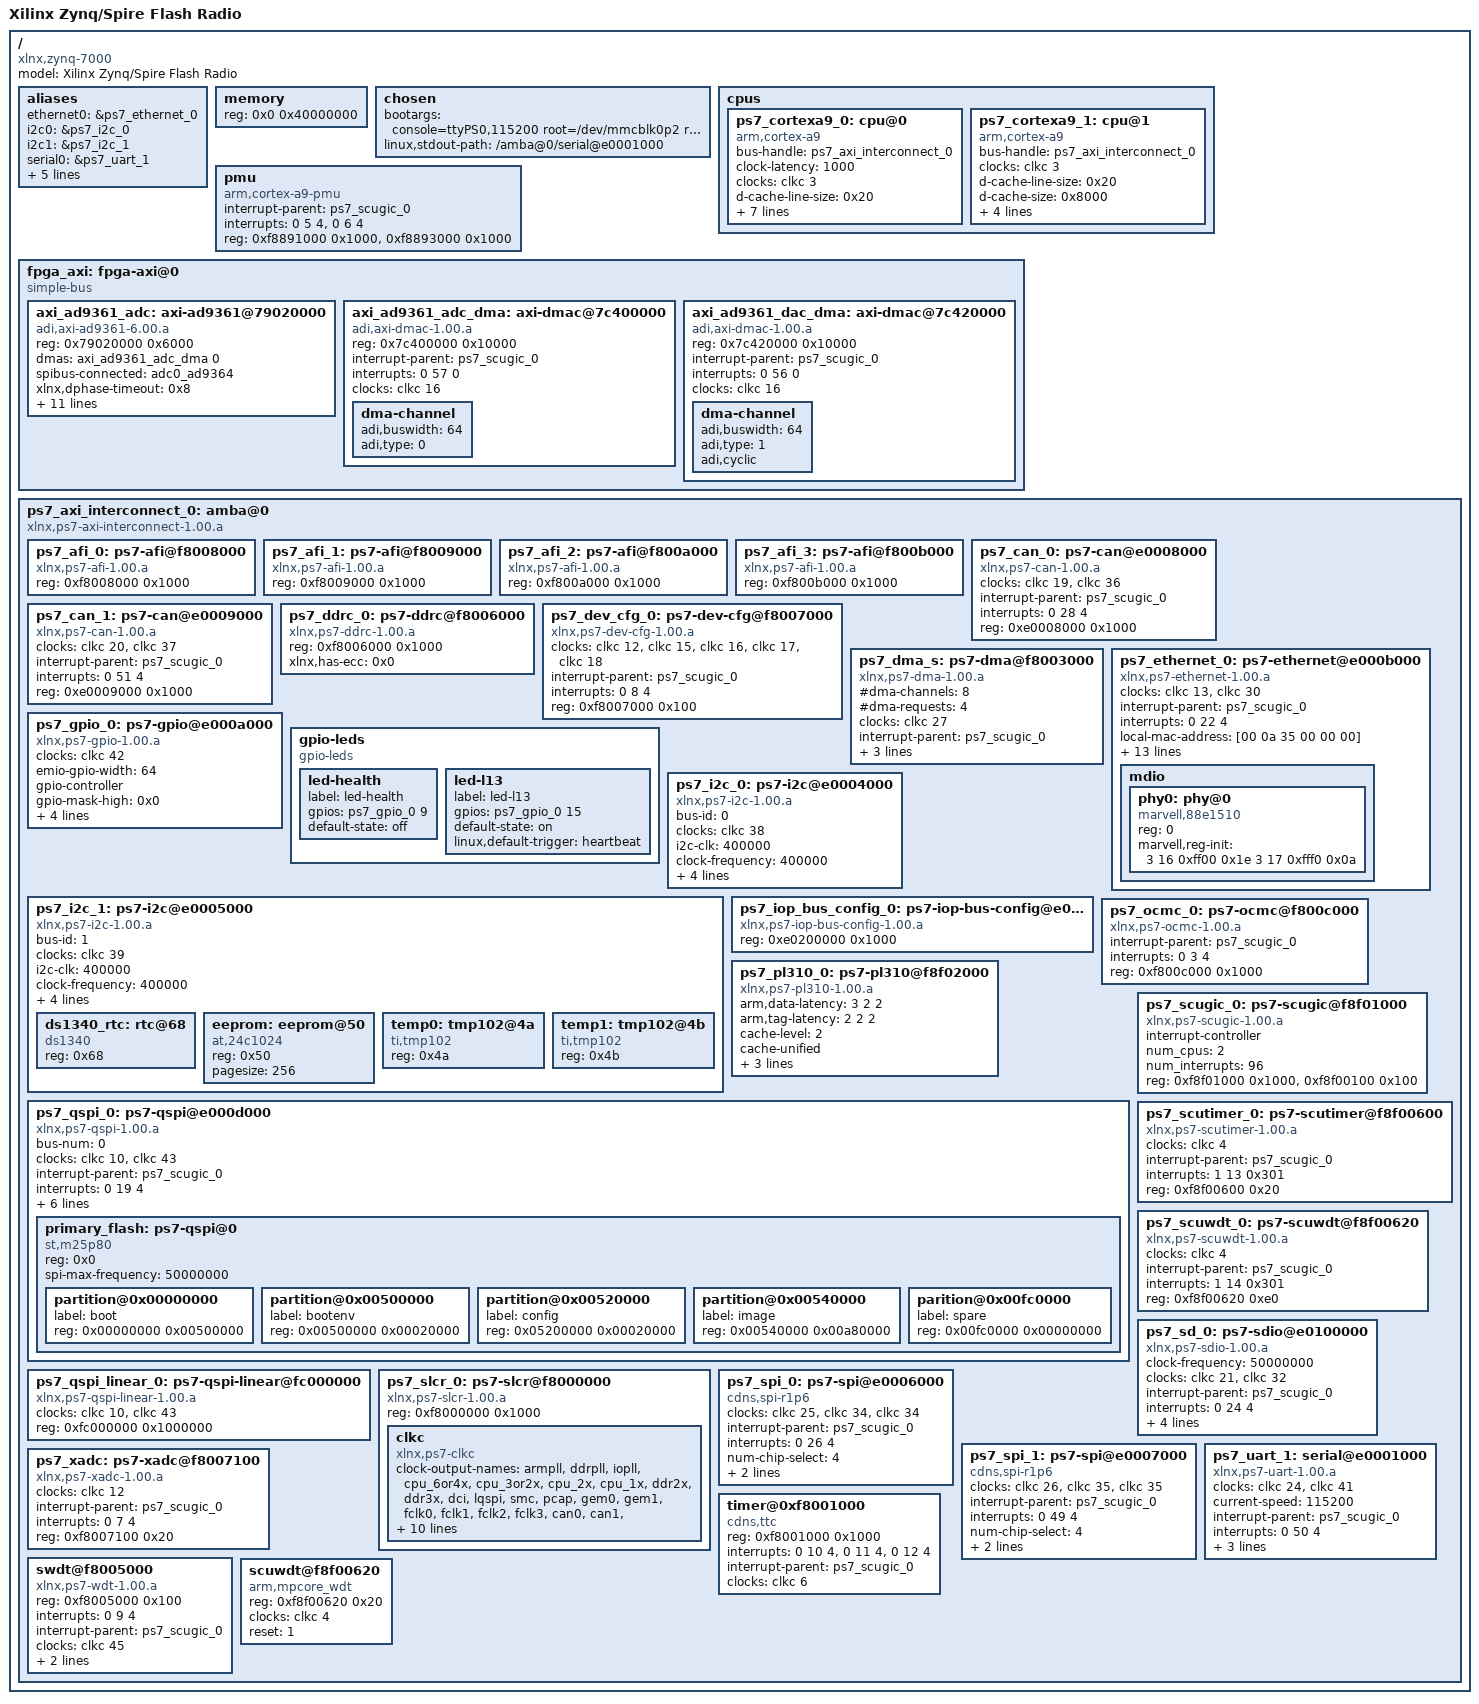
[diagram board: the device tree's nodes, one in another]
/*
 * Device Tree Generator version: 1.1
 *
 * (C) Copyright 2007-2013 Xilinx, Inc.
 * (C) Copyright 2007-2013 Michal Simek
 * (C) Copyright 2007-2012 PetaLogix Qld Pty Ltd
 *
 * Michal SIMEK <monstr@monstr.eu>
 *
 * CAUTION: This file is automatically generated by libgen.
 * Version: Xilinx EDK 2013.4 EDK_2013.4.20131205
 * Today is: Saturday, the 06 of December, 2014; 18:50:28
 *
 * XPS project directory: device-tree_bsp_0
 */

/dts-v1/;
/ {
	#address-cells = <1>;
	#size-cells = <1>;
	compatible = "xlnx,zynq-7000";
	model = "Xilinx Zynq/Spire Flash Radio";
	aliases {
		ethernet0 = &ps7_ethernet_0;
		i2c0 = &ps7_i2c_0;
		i2c1 = &ps7_i2c_1;
		serial0 = &ps7_uart_1;
		spi0 = &ps7_qspi_0;
		spi1 = &ps7_spi_0;
		spi2 = &ps7_spi_1;
		can0 = &ps7_can_0;
		can1 = &ps7_can_1;
	} ;
	memory {
		device_type = "memory";
		reg = <0x0 0x40000000>;
	} ;
	chosen {
		bootargs = "console=ttyPS0,115200 root=/dev/mmcblk0p2 rw earlyprintk rootfstype=ext4 rootwait devtmpfs.mount=0";
		linux,stdout-path = "/amba@0/serial@e0001000";
	} ;
	cpus {
		#address-cells = <1>;
		#size-cells = <0>;
		ps7_cortexa9_0: cpu@0 {
			bus-handle = <&ps7_axi_interconnect_0>;
            clock-latency = <1000>;
            clocks = <&clkc 3>;
			compatible = "arm,cortex-a9";
			d-cache-line-size = <0x20>;
			d-cache-size = <0x8000>;
			device_type = "cpu";
			i-cache-line-size = <0x20>;
			i-cache-size = <0x8000>;
			interrupt-handle = <&ps7_scugic_0>;
            operating-points = <666667 1000000 333334 1000000 222223 1000000>;
			reg = <0x0>;
		} ;
		ps7_cortexa9_1: cpu@1 {
			bus-handle = <&ps7_axi_interconnect_0>;
            clocks = <&clkc 3>;
			compatible = "arm,cortex-a9";
			d-cache-line-size = <0x20>;
			d-cache-size = <0x8000>;
			device_type = "cpu";
			i-cache-line-size = <0x20>;
			i-cache-size = <0x8000>;
			interrupt-handle = <&ps7_scugic_0>;
			reg = <0x1>;
		} ;
	} ;

    pmu {
		compatible = "arm,cortex-a9-pmu";
		interrupt-parent = <&ps7_scugic_0>;
		interrupts = <0 5 4>, <0 6 4>;
		reg = <0xf8891000 0x1000>, <0xf8893000 0x1000>;
		reg-names = "cpu0", "cpu1";
	} ;

    fpga_axi: fpga-axi@0 {
        compatible = "simple-bus";
        #address-cells = <0x1>;
        #size-cells = <0x1>;
        ranges;
		axi_ad9361_adc: axi-ad9361@79020000 {
			compatible = "adi,axi-ad9361-6.00.a";
			reg = <0x79020000 0x6000>;
            dmas = <&axi_ad9361_adc_dma 0>;
            dma-names = "rx";
            spibus-connected = <&adc0_ad9364>;
            xlnx,dphase-timeout = <0x8>;
            xlnx,num-mem = <0x1>;
            xlnx,num-reg = <0x1>;
			xlnx,s-axi-min-size = <0x1ff>;
            xlnx,slv-awidth = <0x20>;
            xlnx,slv-dwidth = <0x20>;
            xlnx,use-wstrb = <0x0>;
            en_agc-gpios = <&ps7_gpio_0 77 0>;
            sync-gpios = <&ps7_gpio_0 78 0>;
            reset-gpios = <&ps7_gpio_0 79 0>;
            enable-gpios = <&ps7_gpio_0 80 0>;
            txnrx-gpios = <&ps7_gpio_0 81 0>;
		} ;
/* TODO: find out if this is necessary to bring back into your img, or
 * to remove from the devtree
 */
/*
        axi_ad9361_dac: axi-ad9361@79024000 {
            compatible = "adi,axi-ad9374-dds-6.00.a";
            reg = <0x79024000 0x1000>;
            clocks = <&adc0_ad9364 13>;
            clock-names = "sampl_clk";
            adi,axi-dds-rate = <1>;
            adi,axi-dds-1-rf-channel;
            dmas = <&axi_ad9361_dac_dma 0>;
            dma-names = "tx";
            dac-sample-frequency = <491520000>;
            xlnx,dphase-timeout = <0x8>;
            xlnx,num-mem = <0x1>;
            xlnx,num-reg = <0x1>;
            xlnx,s-axi-min-size = <0x1ff>;
            xlnx,slv-awidth = <0x20>;
            xlnx,slv-dwidth = <0x20>;
            xlnx,use-wstrb = <0x0>;
        } ;
*/
		axi_ad9361_adc_dma: axi-dmac@7c400000 {
			reg = <0x7c400000 0x10000>;
			compatible = "adi,axi-dmac-1.00.a";
            #dma-cells = <1>;
			interrupt-parent = <&ps7_scugic_0>;
			interrupts = <0 57 0>;
            clocks = <&clkc 16>;
            dma-channel {
                adi,buswidth = <64>;
                adi,type = <0>;
            };
		} ;
		axi_ad9361_dac_dma: axi-dmac@7c420000 {
			reg = <0x7c420000 0x10000>;
			compatible = "adi,axi-dmac-1.00.a";
            #dma-cells = <1>;
			interrupt-parent = <&ps7_scugic_0>;
			interrupts = <0 56 0>;
            clocks = <&clkc 16>;
            dma-channel {
                adi,buswidth = <64>;
                adi,type = <1>;
                adi,cyclic;
            };
		} ;
    };

	ps7_axi_interconnect_0: amba@0 {
		#address-cells = <1>;
		#size-cells = <1>;
		compatible = "xlnx,ps7-axi-interconnect-1.00.a", "simple-bus";
		ranges ;

		ps7_afi_0: ps7-afi@f8008000 {
			compatible = "xlnx,ps7-afi-1.00.a";
			reg = <0xf8008000 0x1000>;
		} ;
		ps7_afi_1: ps7-afi@f8009000 {
			compatible = "xlnx,ps7-afi-1.00.a";
			reg = <0xf8009000 0x1000>;
		} ;
		ps7_afi_2: ps7-afi@f800a000 {
			compatible = "xlnx,ps7-afi-1.00.a";
			reg = <0xf800a000 0x1000>;
		} ;
		ps7_afi_3: ps7-afi@f800b000 {
			compatible = "xlnx,ps7-afi-1.00.a";
			reg = <0xf800b000 0x1000>;
		} ;
		ps7_can_0: ps7-can@e0008000 {
			clock-names = "ref_clk", "aper_clk";
			clocks = <&clkc 19>, <&clkc 36>;
			compatible = "xlnx,ps7-can-1.00.a", "xlnx,ps7-can";
			interrupt-parent = <&ps7_scugic_0>;
			interrupts = <0 28 4>;
			reg = <0xe0008000 0x1000>;
		} ;
		ps7_can_1: ps7-can@e0009000 {
			clock-names = "ref_clk", "aper_clk";
			clocks = <&clkc 20>, <&clkc 37>;
			compatible = "xlnx,ps7-can-1.00.a", "xlnx,ps7-can";
			interrupt-parent = <&ps7_scugic_0>;
			interrupts = <0 51 4>;
			reg = <0xe0009000 0x1000>;
		} ;
		ps7_ddrc_0: ps7-ddrc@f8006000 {
			compatible = "xlnx,ps7-ddrc-1.00.a", "xlnx,ps7-ddrc", "xlnx,zynq-ddrc-1.0";
			reg = <0xf8006000 0x1000>;
			xlnx,has-ecc = <0x0>;
		} ;
		ps7_dev_cfg_0: ps7-dev-cfg@f8007000 {
			clock-names = "ref_clk", "fclk0", "fclk1", "fclk2", "fclk3";
			clocks = <&clkc 12>, <&clkc 15>, <&clkc 16>, <&clkc 17>, <&clkc 18>;
			compatible = "xlnx,ps7-dev-cfg-1.00.a";
			interrupt-parent = <&ps7_scugic_0>;
			interrupts = <0 8 4>;
			reg = <0xf8007000 0x100>;
		} ;
		ps7_dma_s: ps7-dma@f8003000 {
			#dma-cells = <1>;
			#dma-channels = <8>;
			#dma-requests = <4>;
			clock-names = "apb_pclk";
			clocks = <&clkc 27>;
			compatible = "xlnx,ps7-dma-1.00.a", "arm,primecell", "arm,pl330";
			interrupt-names = "abort", "dma0", "dma1", "dma2", "dma3",
				"dma4", "dma5", "dma6", "dma7";
			interrupt-parent = <&ps7_scugic_0>;
			interrupts = <0 13 4>, <0 14 4>, <0 15 4>, <0 16 4>, <0 17 4>, <0 40 4>, <0 41 4>, <0 42 4>, <0 43 4>;
			reg = <0xf8003000 0x1000>;
		} ;
		ps7_ethernet_0: ps7-ethernet@e000b000 {
			#address-cells = <1>;
			#size-cells = <0>;
			clock-names = "ref_clk", "aper_clk";
			clocks = <&clkc 13>, <&clkc 30>;
			compatible = "xlnx,ps7-ethernet-1.00.a";
			interrupt-parent = <&ps7_scugic_0>;
			interrupts = <0 22 4>;
			local-mac-address = [00 0a 35 00 00 00];
			phy-handle = <&phy0>;
			phy-mode = "rgmii-id";
			reg = <0xe000b000 0x1000>;
			xlnx,eth-mode = <0x1>;
			xlnx,has-mdio = <0x1>;
			xlnx,ptp-enet-clock = <111111115>;
            xlnx,enet-reset = "MIO 11";
            xlnx,enet-slcr-1000mbps-div0 = <0x8>;
            xlnx,enet-slcr-1000mbps-div1 = <0x1>;
            xlnx,enet-slcr-100mbps-div0 = <0x8>;
            xlnx,enet-slcr-100mbps-div1 = <0x5>;
            xlnx,enet-slcr-10mbps-div0 = <0x8>;
            xlnx,enet-slcr-10mbps-div1 = <0x32>;
			mdio {
				#address-cells = <1>;
				#size-cells = <0>;
				phy0: phy@0 {
					compatible = "marvell,88e1510";
					device_type = "ethernet-phy";
					reg = <0>;
                    marvell,reg-init=<3 16 0xff00 0x1e 3 17 0xfff0 0x0a>;
				} ;
			} ;
		} ;
		ps7_gpio_0: ps7-gpio@e000a000 {
			#gpio-cells = <2>;
			clocks = <&clkc 42>;
			compatible = "xlnx,ps7-gpio-1.00.a", "xlnx,zynq-gpio-1.0";
			emio-gpio-width = <64>;
			gpio-controller ;
			gpio-mask-high = <0x0>;
			gpio-mask-low = <0x5600>;
			interrupt-parent = <&ps7_scugic_0>;
			interrupts = <0 20 4>;
			reg = <0xe000a000 0x1000>;
		} ;
            /* Named GPIOs, nonspecific (as named on motherboard)
             * linux-gpio currently doesn't appear to support any
             * method of aliasing GPIO names, so we comment this out
             * for now.
             */
/*
        named_gpios {
            fmc_gpios = <&ps7_gpio_0 54 0>,
                        <&ps7_gpio_0 55 0>,
                        <&ps7_gpio_0 56 0>,
                        <&ps7_gpio_0 57 0>,
                        <&ps7_gpio_0 58 0>,
                        <&ps7_gpio_0 59 0>,
                        <&ps7_gpio_0 60 0>,
                        <&ps7_gpio_0 61 0>,
                        <&ps7_gpio_0 62 0>,
                        <&ps7_gpio_0 63 0>,
                        <&ps7_gpio_0 64 0>;

            fmc_status_gpios = <&ps7_gpio_0 65 0>,
                                <&ps7_gpio_0 66 0>,
                                <&ps7_gpio_0 67 0>,
                                <&ps7_gpio_0 68 0>,
                                <&ps7_gpio_0 69 0>,
                                <&ps7_gpio_0 70 0>,
                                <&ps7_gpio_0 71 0>,
                                <&ps7_gpio_0 72 0>;

            fmc_ctrl_gpios = <&ps7_gpio_0 73 0>,
                                <&ps7_gpio_0 74 0>,
                                <&ps7_gpio_0 75 0>,
                                <&ps7_gpio_0 76 0>;
        };
*/
        gpio-leds {
            compatible = "gpio-leds";
            led-health {
                label = "led-health";
                gpios = <&ps7_gpio_0 9 0>;
                default-state = "off";
            };
            led-l13 {
                label = "led-l13";
                gpios = <&ps7_gpio_0 15 0>;
                default-state = "on";
                linux,default-trigger = "heartbeat";
            };
        };

		ps7_i2c_0: ps7-i2c@e0004000 {
			bus-id = <0>;
			clocks = <&clkc 38>;
			compatible = "xlnx,ps7-i2c-1.00.a", "cdns,i2c-r1p10";
			i2c-clk = <400000>;
            clock-frequency = <400000>;
			interrupt-parent = <&ps7_scugic_0>;
			interrupts = <0 25 0>;
			reg = <0xe0004000 0x1000>;
			xlnx,has-interrupt = <0x0>;
		} ;
		ps7_i2c_1: ps7-i2c@e0005000 {
			bus-id = <1>;
			clocks = <&clkc 39>;
			compatible = "xlnx,ps7-i2c-1.00.a", "cdns,i2c-r1p10";
			i2c-clk = <400000>;
            clock-frequency = <400000>;
			interrupt-parent = <&ps7_scugic_0>;
			interrupts = <0 48 0>;
			reg = <0xe0005000 0x1000>;
			xlnx,has-interrupt = <0x0>;
            #address-cells = <1>;
            #size-cells = <0>;
            ds1340_rtc: rtc@68 {
                compatible = "ds1340";
                reg = <0x68>;
            };
            eeprom: eeprom@50 {
                compatible = "at,24c1024";
                reg = <0x50>;
                pagesize = <256>;
            };
            temp0: tmp102@4a {
                compatible = "ti,tmp102";
                reg = <0x4a>;
            };
            temp1: tmp102@4b {
                compatible = "ti,tmp102";
                reg = <0x4b>;
            };
		} ;
		ps7_iop_bus_config_0: ps7-iop-bus-config@e0200000 {
			compatible = "xlnx,ps7-iop-bus-config-1.00.a";
			reg = <0xe0200000 0x1000>;
		} ;
		ps7_ocmc_0: ps7-ocmc@f800c000 {
			compatible = "xlnx,ps7-ocmc-1.00.a", "xlnx,zynq-ocmc-1.0";
			interrupt-parent = <&ps7_scugic_0>;
			interrupts = <0 3 4>;
			reg = <0xf800c000 0x1000>;
		} ;
		ps7_pl310_0: ps7-pl310@f8f02000 {
			arm,data-latency = <3 2 2>;
			arm,tag-latency = <2 2 2>;
			cache-level = <2>;
			cache-unified ;
			compatible = "xlnx,ps7-pl310-1.00.a", "arm,pl310-cache";
			interrupt-parent = <&ps7_scugic_0>;
			interrupts = <0 2 4>;
			reg = <0xf8f02000 0x1000>;
		} ;
		ps7_qspi_0: ps7-qspi@e000d000 {
			#address-cells = <1>;
			#size-cells = <0>;
            bus-num = <0>;
			clock-names = "ref_clk", "aper_clk";
			clocks = <&clkc 10>, <&clkc 43>;
			compatible = "xlnx,ps7-qspi-1.00.a";
			interrupt-parent = <&ps7_scugic_0>;
			interrupts = <0 19 4>;
			is-dual = <0>;
			num-chip-select = <1>;
			reg = <0xe000d000 0x1000>;
			xlnx,fb-clk = <0x1>;
			xlnx,qspi-mode = <0x0>;
            xlnx,qspi-clk-freq-hz = <200000000>;
            primary_flash: ps7-qspi@0 {
                #address-cells = <1>;
                #size-cells = <1>;
                compatible = "st,m25p80";
                reg = <0x0>;
                spi-max-frequency = <50000000>;
                partition@0x00000000 {
                    label = "boot";
                    reg = <0x00000000 0x00500000>;
                };
                partition@0x00500000 {
                    label = "bootenv";
                    reg = <0x00500000 0x00020000>;
                };
                partition@0x00520000 {
                    label = "config";
                    reg = <0x05200000 0x00020000>;
                };
                partition@0x00540000 {
                    label = "image";
                    reg = <0x00540000 0x00a80000>;
                };
                parition@0x00fc0000 {
                    label = "spare";
                    reg = <0x00fc0000 0x00000000>;
                };
            };
		} ;
		ps7_qspi_linear_0: ps7-qspi-linear@fc000000 {
			clock-names = "ref_clk", "aper_clk";
			clocks = <&clkc 10>, <&clkc 43>;
			compatible = "xlnx,ps7-qspi-linear-1.00.a";
			reg = <0xfc000000 0x1000000>;
		} ;
		ps7_scugic_0: ps7-scugic@f8f01000 {
			#address-cells = <2>;
			#interrupt-cells = <3>;
			#size-cells = <1>;
			compatible = "xlnx,ps7-scugic-1.00.a", "arm,cortex-a9-gic", "arm,gic";
			interrupt-controller ;
			num_cpus = <2>;
			num_interrupts = <96>;
			reg = <0xf8f01000 0x1000>, <0xf8f00100 0x100>;
		} ;
		ps7_scutimer_0: ps7-scutimer@f8f00600 {
			clocks = <&clkc 4>;
			compatible = "xlnx,ps7-scutimer-1.00.a", "arm,cortex-a9-twd-timer";
			interrupt-parent = <&ps7_scugic_0>;
			interrupts = <1 13 0x301>;
			reg = <0xf8f00600 0x20>;
		} ;
		ps7_scuwdt_0: ps7-scuwdt@f8f00620 {
			clocks = <&clkc 4>;
			compatible = "xlnx,ps7-scuwdt-1.00.a";
			device_type = "watchdog";
			interrupt-parent = <&ps7_scugic_0>;
			interrupts = <1 14 0x301>;
			reg = <0xf8f00620 0xe0>;
		} ;
		ps7_sd_0: ps7-sdio@e0100000 {
			clock-frequency = <50000000>;
			clock-names = "clk_xin", "clk_ahb";
			clocks = <&clkc 21>, <&clkc 32>;
			compatible = "xlnx,ps7-sdio-1.00.a", "generic-sdhci", "arasan,sdhci-8.9a";
			interrupt-parent = <&ps7_scugic_0>;
			interrupts = <0 24 4>;
			reg = <0xe0100000 0x1000>;
			xlnx,has-cd = <0x0>;
			xlnx,has-power = <0x0>;
			xlnx,has-wp = <0x0>;
		} ;
		ps7_slcr_0: ps7-slcr@f8000000 {
			compatible = "xlnx,ps7-slcr-1.00.a", "xlnx,zynq-slcr", "syscon";
			reg = <0xf8000000 0x1000>;
            #address-cells = <1>;
            #size-cells = <1>;
            ranges;
            clkc: clkc {
                #clock-cells = <1>;
                clock-output-names = "armpll", "ddrpll", "iopll", "cpu_6or4x", "cpu_3or2x",
                    "cpu_2x", "cpu_1x", "ddr2x", "ddr3x", "dci",
                    "lqspi", "smc", "pcap", "gem0", "gem1",
                    "fclk0", "fclk1", "fclk2", "fclk3", "can0",
                    "can1", "sdio0", "sdio1", "uart0", "uart1",
                    "spi0", "spi1", "dma", "usb0_aper", "usb1_aper",
                    "gem0_aper", "gem1_aper", "sdio0_aper", "sdio1_aper", "spi0_aper",
                    "spi1_aper", "can0_aper", "can1_aper", "i2c0_aper", "i2c1_aper",
                    "uart0_aper", "uart1_aper", "gpio_aper", "lqspi_aper", "smc_aper",
                    "swdt", "dbg_trc", "dbg_apb";
                compatible = "xlnx,ps7-clkc";
                fclk-enable = <0xf>;
                ps-clk-frequency = <33333333>;
                reg = <0x100 0x100>;
            } ;
		} ;
		ps7_spi_0: ps7-spi@e0006000 {
			clock-names = "ref_clk", "aper_clk", "pclk";
			clocks = <&clkc 25>, <&clkc 34>, <&clkc 34>;
			compatible = "cdns,spi-r1p6", "xlnx,ps7-spi-1.00.a";
			interrupt-parent = <&ps7_scugic_0>;
			interrupts = <0 26 4>;
			num-chip-select = <4>;
			reg = <0xe0006000 0x1000>;
            #address-cells = <1>;
            #size-cells = <0>;
            speed-hz = <100000000>;
            status = "okay";
		} ;

#define fmc_spi ps7_spi_0

		ps7_spi_1: ps7-spi@e0007000 {
			clock-names = "ref_clk", "aper_clk", "pclk";
			clocks = <&clkc 26>, <&clkc 35>, <&clkc 35>;
			compatible = "cdns,spi-r1p6", "xlnx,ps7-spi-1.00.a";
			interrupt-parent = <&ps7_scugic_0>;
			interrupts = <0 49 4>;
			num-chip-select = <4>;
			reg = <0xe0007000 0x1000>;
            #address-cells = <1>;
            #size-cells = <0>;
            speed-hz = <100000000>;
		} ;
		ps7_uart_1: serial@e0001000 {
			clock-names = "ref_clk", "aper_clk";
			clocks = <&clkc 24>, <&clkc 41>;
			compatible = "xlnx,ps7-uart-1.00.a", "xlnx,xuartps";
			current-speed = <115200>;
			device_type = "serial";
			interrupt-parent = <&ps7_scugic_0>;
			interrupts = <0 50 4>;
			port-number = <0>;
			reg = <0xe0001000 0x1000>;
			xlnx,has-modem = <0x0>;
		} ;
		ps7_xadc: ps7-xadc@f8007100 {
			clocks = <&clkc 12>;
			compatible = "xlnx,ps7-xadc-1.00.a";
			interrupt-parent = <&ps7_scugic_0>;
			interrupts = <0 7 4>;
			reg = <0xf8007100 0x20>;
		} ;

/* From zynq.dtsi */
        timer@0xf8001000 {
            compatible = "cdns,ttc";
            reg = <0xf8001000 0x1000>;
            interrupts = <0 10 4>, <0 11 4>, <0 12 4>;
            interrupt-parent = <&ps7_scugic_0>;
            clocks = <&clkc 6>;
        };
/*
        timer@f8f00600 {
            compatible = "arm,cortex-a9-twd-timer";
            reg = <0xf8f00600 0x20>;
            interrupts = <1 13 0x301>;
            clocks = <&clkc 4>;
            interrupt-parent = <&ps7_scugic_0>;
        };
*/
        swdt@f8005000 {
            device_type = "watchdog";
            compatible = "xlnx,ps7-wdt-1.00.a", "xlnx,zynq-wdt-1.00-a";
            reg = <0xf8005000 0x100>;
            interrupts = <0 9 4>;
            interrupt-parent = <&ps7_scugic_0>;
            clocks = <&clkc 45>;
            reset = <0>;
            timeout = <10>;
        };

        scuwdt@f8f00620 {
            device_type = "watchdog";
            compatible = "arm,mpcore_wdt";
            reg = <0xf8f00620 0x20>;
            clocks = <&clkc 4>;
            reset = <1>;
        };
/* end from zynq.dtsi */
	} ;
} ;

#include "adi-flash.dtsi"
